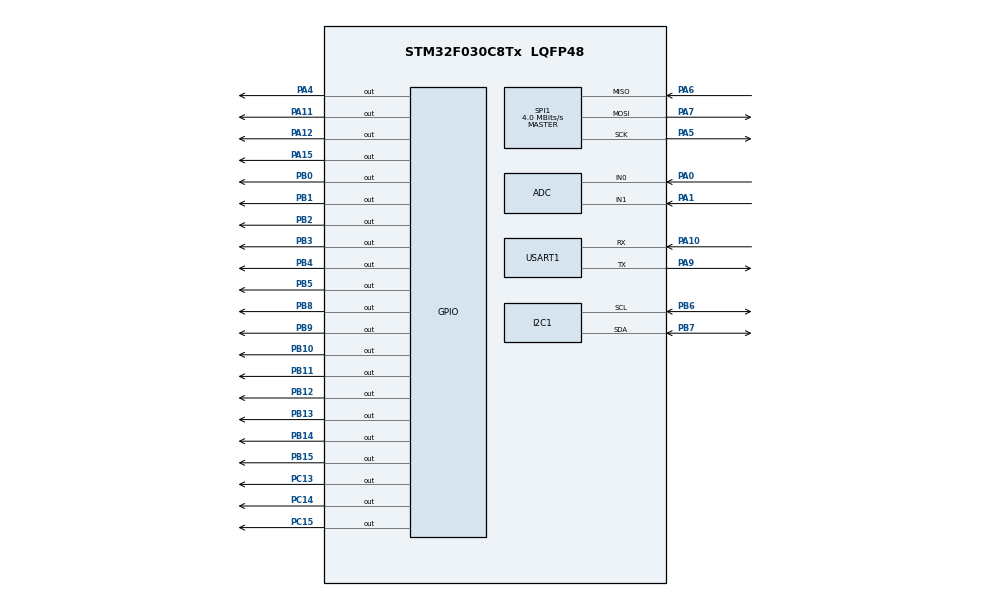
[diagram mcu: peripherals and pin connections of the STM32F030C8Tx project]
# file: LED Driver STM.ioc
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FREERTOS.Tasks01=defaultTask,0,128,StartDefaultTask,Default,NULL,Dynamic,NULL,NULL;updateLeds,-2,128,startUpdateLeds,Default,NULL,Dynamic,NULL,NULL
Mcu.Family=STM32F0
Mcu.Name=STM32F030C8Tx
Mcu.Package=LQFP48
NVIC.TIM1_BRK_UP_TRG_COM_IRQn=true\:0\:0\:false\:false\:true\:false\:false\:true
NVIC.TimeBase=TIM1_BRK_UP_TRG_COM_IRQn
NVIC.TimeBaseIP=TIM1
PA0.Mode=IN0
PA0.Signal=ADC_IN0
PA1.Mode=IN1
PA1.Signal=ADC_IN1
PA10.Mode=Asynchronous
PA10.Signal=USART1_RX
PA11.GPIO_PuPd=GPIO_PULLDOWN
PA11.Signal=GPIO_Output
PA12.GPIO_PuPd=GPIO_PULLDOWN
PA12.Signal=GPIO_Output
PA13.Mode=Serial_Wire
PA13.Signal=SYS_SWDIO
PA14.Mode=Serial_Wire
PA14.Signal=SYS_SWCLK
PA15.GPIO_PuPd=GPIO_PULLDOWN
PA15.Signal=GPIO_Output
PA4.Signal=GPIO_Output
PA5.Mode=Full_Duplex_Master
PA5.Signal=SPI1_SCK
PA6.Mode=Full_Duplex_Master
PA6.Signal=SPI1_MISO
PA7.Mode=Full_Duplex_Master
PA7.Signal=SPI1_MOSI
PA9.Mode=Asynchronous
PA9.Signal=USART1_TX
PB0.GPIO_PuPd=GPIO_PULLDOWN
PB0.Signal=GPIO_Output
PB1.GPIO_PuPd=GPIO_PULLDOWN
PB1.Signal=GPIO_Output
PB10.GPIO_PuPd=GPIO_PULLDOWN
PB10.Signal=GPIO_Output
PB11.GPIO_PuPd=GPIO_PULLDOWN
PB11.Signal=GPIO_Output
PB12.GPIO_PuPd=GPIO_PULLDOWN
PB12.Signal=GPIO_Output
PB13.GPIO_PuPd=GPIO_PULLDOWN
PB13.Signal=GPIO_Output
PB14.GPIO_PuPd=GPIO_PULLDOWN
PB14.Signal=GPIO_Output
PB15.GPIO_PuPd=GPIO_PULLDOWN
PB15.Signal=GPIO_Output
PB2.GPIO_PuPd=GPIO_PULLDOWN
PB2.Signal=GPIO_Output
PB3.GPIO_PuPd=GPIO_PULLDOWN
PB3.Signal=GPIO_Output
PB4.GPIO_PuPd=GPIO_PULLDOWN
PB4.Signal=GPIO_Output
PB5.GPIO_PuPd=GPIO_PULLDOWN
PB5.Signal=GPIO_Output
PB6.Mode=I2C
PB6.Signal=I2C1_SCL
PB7.Mode=I2C
PB7.Signal=I2C1_SDA
PB8.GPIO_PuPd=GPIO_PULLDOWN
PB8.Signal=GPIO_Output
PB9.GPIO_PuPd=GPIO_PULLDOWN
PB9.Signal=GPIO_Output
PC13.GPIO_PuPd=GPIO_PULLDOWN
PC13.Signal=GPIO_Output
PC14-OSC32_IN.GPIO_PuPd=GPIO_PULLDOWN
PC14-OSC32_IN.Signal=GPIO_Output
PC15-OSC32_OUT.GPIO_PuPd=GPIO_PULLDOWN
PC15-OSC32_OUT.Signal=GPIO_Output
PF0-OSC_IN.Mode=HSE-External-Oscillator
PF0-OSC_IN.Signal=RCC_OSC_IN
PF1-OSC_OUT.Mode=HSE-External-Oscillator
PF1-OSC_OUT.Signal=RCC_OSC_OUT
ProjectManager.HeapSize=0x200
ProjectManager.StackSize=0x400
ProjectManager.TargetToolchain=STM32CubeIDE
RCC.AHBFreq_Value=8000000
RCC.APB1Freq_Value=8000000
RCC.APB1TimFreq_Value=8000000
RCC.HCLKFreq_Value=8000000
RCC.PLLSourceVirtual=RCC_PLLSOURCE_HSE
RCC.SYSCLKSource=RCC_SYSCLKSOURCE_HSE
SPI1.BaudRatePrescaler=SPI_BAUDRATEPRESCALER_2
SPI1.CLKPhase=SPI_PHASE_2EDGE
SPI1.CLKPolarity=SPI_POLARITY_HIGH
SPI1.CalculateBaudRate=4.0 MBits/s
SPI1.DataSize=SPI_DATASIZE_8BIT
SPI1.Direction=SPI_DIRECTION_2LINES
SPI1.Mode=SPI_MODE_MASTER
SPI1.TIMode=SPI_TIMODE_DISABLE
SPI1.VirtualType=VM_MASTER
USART1.VirtualMode-Asynchronous=VM_ASYNC
VP_FREERTOS_VS_CMSIS_V1.Mode=CMSIS_V1
VP_SYS_VS_tim1.Mode=TIM1
board=custom

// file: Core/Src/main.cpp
/* USER CODE BEGIN Header */
/**
  ******************************************************************************
  * @file           : main.c
  * @brief          : Main program body
  ******************************************************************************
  * @attention
  *
  * <h2><center>&copy; Copyright (c) 2020 STMicroelectronics.
  * All rights reserved.</center></h2>
  *
  * This software component is licensed by ST under BSD 3-Clause license,
  * the "License"; You may not use this file except in compliance with the
  * License. You may obtain a copy of the License at:
  *                        opensource.org/licenses/BSD-3-Clause
  *
  ******************************************************************************
  */
/* USER CODE END Header */
#include "main.h"
#include "cmsis_os.h"

/* USER CODE BEGIN Includes */
#include "common.h"
#include "run.h"

/* USER CODE END Includes */

ADC_HandleTypeDef hadc;

I2C_HandleTypeDef hi2c1;

SPI_HandleTypeDef hspi1;

UART_HandleTypeDef huart1;

osThreadId defaultTaskHandle;
osThreadId updateLedsHandle;

void SystemClock_Config(void);
static void MX_GPIO_Init(void);
static void MX_ADC_Init(void);
static void MX_I2C1_Init(void);
static void MX_SPI1_Init(void);
static void MX_USART1_UART_Init(void);
void StartDefaultTask(void const * argument);
void startUpdateLeds(void const * argument);

int main(void)
{

  /* MCU Configuration--------------------------------------------------------*/

  /* Reset of all peripherals, Initializes the Flash interface and the Systick. */
  HAL_Init();

  /* Configure the system clock */
  SystemClock_Config();

  /* Initialize all configured peripherals */
  MX_GPIO_Init();
  MX_ADC_Init();
  MX_I2C1_Init();
  MX_SPI1_Init();
  MX_USART1_UART_Init();

  /* Create the thread(s) */
  /* definition and creation of defaultTask */
  osThreadDef(defaultTask, StartDefaultTask, osPriorityNormal, 0, 128);
  defaultTaskHandle = osThreadCreate(osThread(defaultTask), NULL);

  /* definition and creation of updateLeds */
  osThreadDef(updateLeds, startUpdateLeds, osPriorityLow, 0, 128);
  updateLedsHandle = osThreadCreate(osThread(updateLeds), NULL);

  /* Start scheduler */
  osKernelStart();

  /* We should never get here as control is now taken by the scheduler */
  /* Infinite loop */
    while (1)
    {

    }
}

void SystemClock_Config(void)
{
  RCC_OscInitTypeDef RCC_OscInitStruct = {0};
  RCC_ClkInitTypeDef RCC_ClkInitStruct = {0};
  RCC_PeriphCLKInitTypeDef PeriphClkInit = {0};

  /** Initializes the RCC Oscillators according to the specified parameters
  * in the RCC_OscInitTypeDef structure.
  */
  RCC_OscInitStruct.OscillatorType = RCC_OSCILLATORTYPE_HSI|RCC_OSCILLATORTYPE_HSI14
                              |RCC_OSCILLATORTYPE_HSE;
  RCC_OscInitStruct.HSEState = RCC_HSE_ON;
  RCC_OscInitStruct.HSIState = RCC_HSI_ON;
  RCC_OscInitStruct.HSI14State = RCC_HSI14_ON;
  RCC_OscInitStruct.HSICalibrationValue = RCC_HSICALIBRATION_DEFAULT;
  RCC_OscInitStruct.HSI14CalibrationValue = 16;
  RCC_OscInitStruct.PLL.PLLState = RCC_PLL_NONE;
  if (HAL_RCC_OscConfig(&RCC_OscInitStruct) != HAL_OK)
  {
    Error_Handler();
  }
  /** Initializes the CPU, AHB and APB buses clocks
  */
  RCC_ClkInitStruct.ClockType = RCC_CLOCKTYPE_HCLK|RCC_CLOCKTYPE_SYSCLK
                              |RCC_CLOCKTYPE_PCLK1;
  RCC_ClkInitStruct.SYSCLKSource = RCC_SYSCLKSOURCE_HSE;
  RCC_ClkInitStruct.AHBCLKDivider = RCC_SYSCLK_DIV1;
  RCC_ClkInitStruct.APB1CLKDivider = RCC_HCLK_DIV1;

  if (HAL_RCC_ClockConfig(&RCC_ClkInitStruct, FLASH_LATENCY_0) != HAL_OK)
  {
    Error_Handler();
  }
  PeriphClkInit.PeriphClockSelection = RCC_PERIPHCLK_USART1|RCC_PERIPHCLK_I2C1;
  PeriphClkInit.Usart1ClockSelection = RCC_USART1CLKSOURCE_PCLK1;
  PeriphClkInit.I2c1ClockSelection = RCC_I2C1CLKSOURCE_HSI;
  if (HAL_RCCEx_PeriphCLKConfig(&PeriphClkInit) != HAL_OK)
  {
    Error_Handler();
  }
}

static void MX_ADC_Init(void)
{

  ADC_ChannelConfTypeDef sConfig = {0};

  /** Configure the global features of the ADC (Clock, Resolution, Data Alignment and number of conversion)
  */
  hadc.Instance = ADC1;
  hadc.Init.ClockPrescaler = ADC_CLOCK_ASYNC_DIV1;
  hadc.Init.Resolution = ADC_RESOLUTION_12B;
  hadc.Init.DataAlign = ADC_DATAALIGN_RIGHT;
  hadc.Init.ScanConvMode = ADC_SCAN_DIRECTION_FORWARD;
  hadc.Init.EOCSelection = ADC_EOC_SINGLE_CONV;
  hadc.Init.LowPowerAutoWait = DISABLE;
  hadc.Init.LowPowerAutoPowerOff = DISABLE;
  hadc.Init.ContinuousConvMode = DISABLE;
  hadc.Init.DiscontinuousConvMode = DISABLE;
  hadc.Init.ExternalTrigConv = ADC_SOFTWARE_START;
  hadc.Init.ExternalTrigConvEdge = ADC_EXTERNALTRIGCONVEDGE_NONE;
  hadc.Init.DMAContinuousRequests = DISABLE;
  hadc.Init.Overrun = ADC_OVR_DATA_PRESERVED;
  if (HAL_ADC_Init(&hadc) != HAL_OK)
  {
    Error_Handler();
  }
  /** Configure for the selected ADC regular channel to be converted.
  */
  sConfig.Channel = ADC_CHANNEL_0;
  sConfig.Rank = ADC_RANK_CHANNEL_NUMBER;
  sConfig.SamplingTime = ADC_SAMPLETIME_1CYCLE_5;
  if (HAL_ADC_ConfigChannel(&hadc, &sConfig) != HAL_OK)
  {
    Error_Handler();
  }
  /** Configure for the selected ADC regular channel to be converted.
  */
  sConfig.Channel = ADC_CHANNEL_1;
  if (HAL_ADC_ConfigChannel(&hadc, &sConfig) != HAL_OK)
  {
    Error_Handler();
  }

}

static void MX_I2C1_Init(void)
{

  hi2c1.Instance = I2C1;
  hi2c1.Init.Timing = 0x2000090E;
  hi2c1.Init.OwnAddress1 = 0;
  hi2c1.Init.AddressingMode = I2C_ADDRESSINGMODE_7BIT;
  hi2c1.Init.DualAddressMode = I2C_DUALADDRESS_DISABLE;
  hi2c1.Init.OwnAddress2 = 0;
  hi2c1.Init.OwnAddress2Masks = I2C_OA2_NOMASK;
  hi2c1.Init.GeneralCallMode = I2C_GENERALCALL_DISABLE;
  hi2c1.Init.NoStretchMode = I2C_NOSTRETCH_DISABLE;
  if (HAL_I2C_Init(&hi2c1) != HAL_OK)
  {
    Error_Handler();
  }
  /** Configure Analogue filter
  */
  if (HAL_I2CEx_ConfigAnalogFilter(&hi2c1, I2C_ANALOGFILTER_ENABLE) != HAL_OK)
  {
    Error_Handler();
  }
  /** Configure Digital filter
  */
  if (HAL_I2CEx_ConfigDigitalFilter(&hi2c1, 0) != HAL_OK)
  {
    Error_Handler();
  }

}

static void MX_SPI1_Init(void)
{

  /* SPI1 parameter configuration*/
  hspi1.Instance = SPI1;
  hspi1.Init.Mode = SPI_MODE_MASTER;
  hspi1.Init.Direction = SPI_DIRECTION_2LINES;
  hspi1.Init.DataSize = SPI_DATASIZE_8BIT;
  hspi1.Init.CLKPolarity = SPI_POLARITY_HIGH;
  hspi1.Init.CLKPhase = SPI_PHASE_2EDGE;
  hspi1.Init.NSS = SPI_NSS_SOFT;
  hspi1.Init.BaudRatePrescaler = SPI_BAUDRATEPRESCALER_2;
  hspi1.Init.FirstBit = SPI_FIRSTBIT_MSB;
  hspi1.Init.TIMode = SPI_TIMODE_DISABLE;
  hspi1.Init.CRCCalculation = SPI_CRCCALCULATION_DISABLE;
  hspi1.Init.CRCPolynomial = 7;
  hspi1.Init.CRCLength = SPI_CRC_LENGTH_DATASIZE;
  hspi1.Init.NSSPMode = SPI_NSS_PULSE_DISABLE;
  if (HAL_SPI_Init(&hspi1) != HAL_OK)
  {
    Error_Handler();
  }

}

static void MX_USART1_UART_Init(void)
{

  huart1.Instance = USART1;
  huart1.Init.BaudRate = 38400;
  huart1.Init.WordLength = UART_WORDLENGTH_8B;
  huart1.Init.StopBits = UART_STOPBITS_1;
  huart1.Init.Parity = UART_PARITY_NONE;
  huart1.Init.Mode = UART_MODE_TX_RX;
  huart1.Init.HwFlowCtl = UART_HWCONTROL_NONE;
  huart1.Init.OverSampling = UART_OVERSAMPLING_16;
  huart1.Init.OneBitSampling = UART_ONE_BIT_SAMPLE_DISABLE;
  huart1.AdvancedInit.AdvFeatureInit = UART_ADVFEATURE_NO_INIT;
  if (HAL_UART_Init(&huart1) != HAL_OK)
  {
    Error_Handler();
  }

}

static void MX_GPIO_Init(void)
{
  GPIO_InitTypeDef GPIO_InitStruct = {0};

  /* GPIO Ports Clock Enable */
  __HAL_RCC_GPIOC_CLK_ENABLE();
  __HAL_RCC_GPIOF_CLK_ENABLE();
  __HAL_RCC_GPIOA_CLK_ENABLE();
  __HAL_RCC_GPIOB_CLK_ENABLE();

  /*Configure GPIO pin Output Level */
  HAL_GPIO_WritePin(GPIOC, GPIO_PIN_13|GPIO_PIN_14|GPIO_PIN_15, GPIO_PIN_RESET);

  /*Configure GPIO pin Output Level */
  HAL_GPIO_WritePin(GPIOA, GPIO_PIN_4|GPIO_PIN_11|GPIO_PIN_12|GPIO_PIN_15, GPIO_PIN_RESET);

  /*Configure GPIO pin Output Level */
  HAL_GPIO_WritePin(GPIOB, GPIO_PIN_0|GPIO_PIN_1|GPIO_PIN_2|GPIO_PIN_10
                          |GPIO_PIN_11|GPIO_PIN_12|GPIO_PIN_13|GPIO_PIN_14
                          |GPIO_PIN_15|GPIO_PIN_3|GPIO_PIN_4|GPIO_PIN_5
                          |GPIO_PIN_8|GPIO_PIN_9, GPIO_PIN_RESET);

  /*Configure GPIO pins : PC13 PC14 PC15 */
  GPIO_InitStruct.Pin = GPIO_PIN_13|GPIO_PIN_14|GPIO_PIN_15;
  GPIO_InitStruct.Mode = GPIO_MODE_OUTPUT_PP;
  GPIO_InitStruct.Pull = GPIO_PULLDOWN;
  GPIO_InitStruct.Speed = GPIO_SPEED_FREQ_LOW;
  HAL_GPIO_Init(GPIOC, &GPIO_InitStruct);

  /*Configure GPIO pin : PA4 */
  GPIO_InitStruct.Pin = GPIO_PIN_4;
  GPIO_InitStruct.Mode = GPIO_MODE_OUTPUT_PP;
  GPIO_InitStruct.Pull = GPIO_NOPULL;
  GPIO_InitStruct.Speed = GPIO_SPEED_FREQ_LOW;
  HAL_GPIO_Init(GPIOA, &GPIO_InitStruct);

  /*Configure GPIO pins : PB0 PB1 PB2 PB10
                           PB11 PB12 PB13 PB14
                           PB15 PB3 PB4 PB5
                           PB8 PB9 */
  GPIO_InitStruct.Pin = GPIO_PIN_0|GPIO_PIN_1|GPIO_PIN_2|GPIO_PIN_10
                          |GPIO_PIN_11|GPIO_PIN_12|GPIO_PIN_13|GPIO_PIN_14
                          |GPIO_PIN_15|GPIO_PIN_3|GPIO_PIN_4|GPIO_PIN_5
                          |GPIO_PIN_8|GPIO_PIN_9;
  GPIO_InitStruct.Mode = GPIO_MODE_OUTPUT_PP;
  GPIO_InitStruct.Pull = GPIO_PULLDOWN;
  GPIO_InitStruct.Speed = GPIO_SPEED_FREQ_LOW;
  HAL_GPIO_Init(GPIOB, &GPIO_InitStruct);

  /*Configure GPIO pins : PA11 PA12 PA15 */
  GPIO_InitStruct.Pin = GPIO_PIN_11|GPIO_PIN_12|GPIO_PIN_15;
  GPIO_InitStruct.Mode = GPIO_MODE_OUTPUT_PP;
  GPIO_InitStruct.Pull = GPIO_PULLDOWN;
  GPIO_InitStruct.Speed = GPIO_SPEED_FREQ_LOW;
  HAL_GPIO_Init(GPIOA, &GPIO_InitStruct);

}

void StartDefaultTask(void const * argument)
{
  for(;;)
  {
    osDelay(1);
  }
}

void startUpdateLeds(void const * argument)
{
  /* USER CODE BEGIN startUpdateLeds */
  /* Infinite loop */
	run();
  /* USER CODE END startUpdateLeds */
}

void HAL_TIM_PeriodElapsedCallback(TIM_HandleTypeDef *htim)
{
  if (htim->Instance == TIM1) {
    HAL_IncTick();
  }
}

void Error_Handler(void)
{
}

/************************ (C) COPYRIGHT STMicroelectronics *****END OF FILE****/
